# myChip register map
Vendor: ARM Ltd.; Series: ARMCM3; File version: 1.2
CPU: CM3 r2p1, little endian, no MPU, no FPU, 3 interrupt priority bits
Registers are 32-bit, read-write, reset 0x0 unless marked. A register's access mark holds for its fields unless they carry their own. Offsets are from the block's base; [hi:lo] are bit positions; {n}, {i} and the like mark numbered series.

## RCU
Base 0x40020000
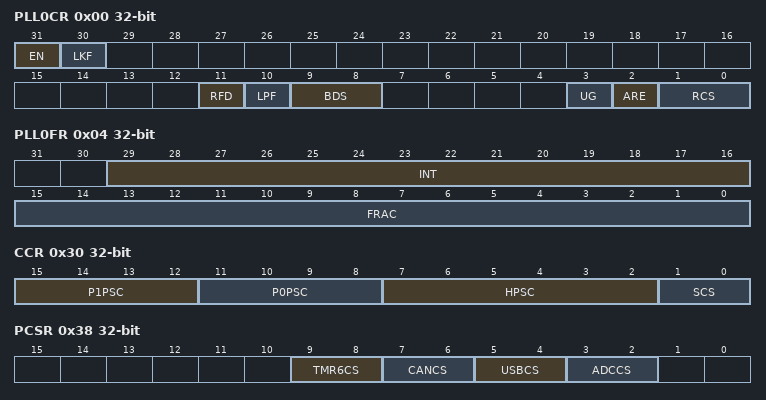
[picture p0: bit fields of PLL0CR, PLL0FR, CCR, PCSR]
0x00 PLL0CR — PLL0 Control Register
  [31] EN — PLL0使能(PLL0 Enable)
  [30] LKF ro — PLL0锁定标志(PLL0 Lock Flag)
  [11] RFD — PLL0参考前除频(PLL0 Refer Clock Division)
  [10] LPF — PLL0 LPF配置(PLL0 LPF Config)
  [9:8] BDS — PLL0 VCO振荡频率范围控制(PLL0 Band Selection)
  [3] UG — PLL0倍频系数更新事件(PLL0 Update Generate)
  [2] ARE — PLL0自动加载使能(PLL0 AutoReload Enable)
  [1:0] RCS — PLL0参考时钟源(PLL0 Refer Clock Selection)
0x04 PLL0FR — PLL0 Fractional Register
  [29:16] INT — PLL0倍频系数整数部分(PLL0 Integer part of multiplication factor)
  [15:0] FRAC — PLL0倍频系数小数部分(PLL0 Fractional part of multiplication factor)
0x30 CCR — System Clock Config Register
  [15:12] P1PSC — APB1时钟分频配置(APB1 Clock Prescale)
  [11:8] P0PSC — APB0时钟分频配置(APB0 Clock Prescale)
  [7:2] HPSC — AHB时钟分频配置(AHB Clock Prescale)
  [1:0] SCS — 系统时钟源选择(System Clock Selection)
0x38 PCSR — Peripheral Function Clock Source Register
  [9:8] TMR6CS — TMR6时钟源选择(TMR6 Clock Source Selection)
  [7:6] CANCS — CAN时钟源选择(CAN Clock Source Selection)
  [5:4] USBCS — USB时钟源选择(USB Clock Source Selection)
  [3:2] ADCCS — ADC时钟源选择(ADC Clock Source Selection)
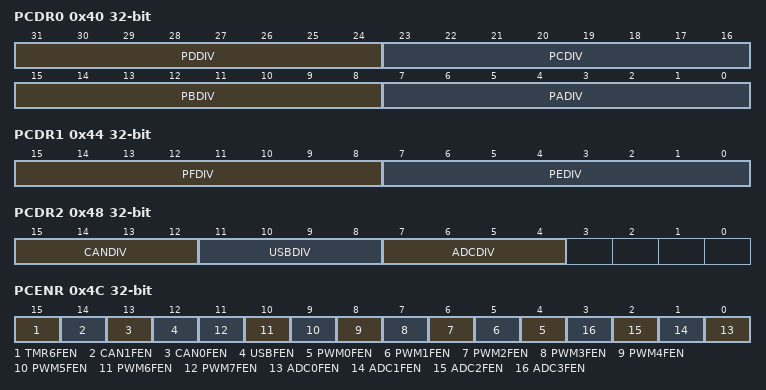
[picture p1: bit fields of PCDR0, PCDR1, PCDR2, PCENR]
0x40 PCDR0 — Peripheral Function Clock Division Register0
  [31:24] PDDIV — GPIOD消抖时钟分频(GPIOD Debounce Clock Division)
  [23:16] PCDIV — GPIOC消抖时钟分频(GPIOC Debounce Clock Division)
  [15:8] PBDIV — GPIOB消抖时钟分频(GPIOB Debounce Clock Division)
  [7:0] PADIV — GPIOA消抖时钟分频(GPIOA Debounce Clock Division)
0x44 PCDR1 — Peripheral Function Clock Division Register1
  [15:8] PFDIV — GPIOF消抖时钟分频(GPIOF Debounce Clock Division)
  [7:0] PEDIV — GPIOE消抖时钟分频(GPIOE Debounce Clock Division)
0x48 PCDR2 — Peripheral Function Clock Division Register2
  [15:12] CANDIV — CAN时钟分频选择(CAN Clock Division)
  [11:8] USBDIV — USB时钟分频选择(USB Clock Division)
  [7:4] ADCDIV — ADC时钟分频选择(ADC Clock Division)
0x4C PCENR — Peripheral Function Clock Enable Register
  [15] TMR6FEN — TMR6功能时钟使能(TMR6 Function Clock Enable)
  [14] CAN1FEN — CAN1功能时钟使能(CAN1 Function Clock Enable)
  [13] CAN0FEN — CAN0功能时钟使能(CAN0 Function Clock Enable)
  [12] USBFEN — USB功能时钟使能(USB Function Clock Enable)
  [n+4] PWM{n}FEN (n=0..7) — PWM{n}功能时钟使能(PWM{n} Function Clock Enable)
  [n] ADC{n}FEN (n=0..3) — ADC{n}功能时钟使能(ADC{n} Function Clock Enable)
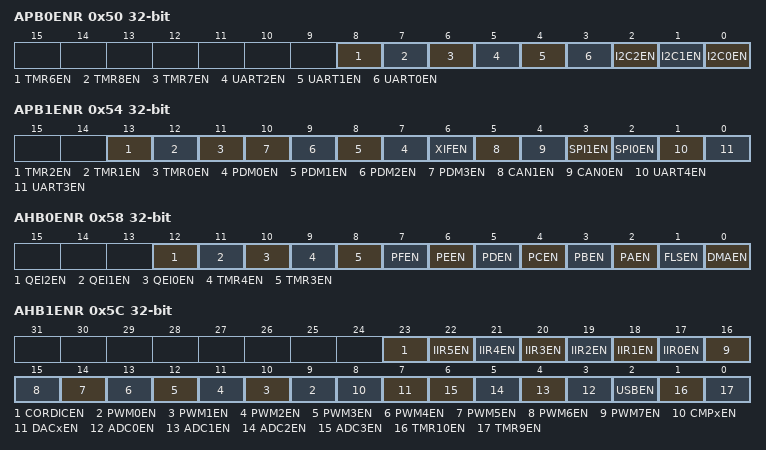
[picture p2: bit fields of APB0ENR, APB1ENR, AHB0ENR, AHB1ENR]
0x50 APB0ENR — APB0 Peripheral Clock Enable Register
  [8] TMR6EN — TMR6时钟使能(TMR6 Clock Enable)
  [7] TMR8EN — TMR8时钟使能(TMR8 Clock Enable)
  [6] TMR7EN — TMR7时钟使能(TMR7 Clock Enable)
  [5] UART2EN — UART2时钟使能(UART2 Clock Enable)
  [4] UART1EN — UART1时钟使能(UART1 Clock Enable)
  [3] UART0EN — UART0时钟使能(UART0 Clock Enable)
  [2] I2C2EN — I2C2时钟使能(I2C2 Clock Enable)
  [1] I2C1EN — I2C1时钟使能(I2C1 Clock Enable)
  [0] I2C0EN — I2C0时钟使能(I2C0 Clock Enable)
0x54 APB1ENR — APB1 Peripheral Clock Enable Register
  [13] TMR2EN — TMR2时钟使能(TMR2 Clock Enable)
  [12] TMR1EN — TMR1时钟使能(TMR1 Clock Enable)
  [11] TMR0EN — TMR0时钟使能(TMR0 Clock Enable)
  [n+7] PDM{n}EN (n=0..3) — PDM{n}时钟使能(PDM{n} Clock Enable)
  [6] XIFEN — XIF时钟使能(XIF Clock Enable)
  [5] CAN1EN — CAN1时钟使能(CAN1 Clock Enable)
  [4] CAN0EN — CAN0时钟使能(CAN0 Clock Enable)
  [3] SPI1EN — SPI1时钟使能(SPI1 Clock Enable)
  [2] SPI0EN — SPI0时钟使能(SPI0 Clock Enable)
  [1] UART4EN — UART4时钟使能(UART4 Clock Enable)
  [0] UART3EN — UART3时钟使能(UART3 Clock Enable)
0x58 AHB0ENR — AHB0 Peripheral Clock Enable Register
  [12] QEI2EN — QEI2时钟使能(QEI2 Clock Enable)
  [11] QEI1EN — QEI1时钟使能(QEI1 Clock Enable)
  [10] QEI0EN — QEI0时钟使能(QEI0 Clock Enable)
  [9] TMR4EN — TMR4时钟使能(TMR4 Clock Enable)
  [8] TMR3EN — TMR3时钟使能(TMR3 Clock Enable)
  [7] PFEN — GPIOF时钟使能(GPIOF Clock Enable)
  [6] PEEN — GPIOE时钟使能(GPIOE Clock Enable)
  [5] PDEN — GPIOD时钟使能(GPIOD Clock Enable)
  [4] PCEN — GPIOC时钟使能(GPIOC Clock Enable)
  [3] PBEN — GPIOB时钟使能(GPIOB Clock Enable)
  [2] PAEN — GPIOA时钟使能(GPIOA Clock Enable)
  [1] FLSEN — FLASH时钟使能(FLASH Clock Enable)
  [0] DMAEN — DMA时钟使能(DMA Clock Enable)
0x5C AHB1ENR — AHB1 Peripheral Clock Enable Register
  [23] CORDICEN — CORDIC时钟使能(CORDIC Clock Enable)
  [n+17] IIR{n}EN (n=0..5) — IIR{n}时钟使能(IIR{n} Clock Enable)
  [n+9] PWM{n}EN (n=0..7) — PWM{n}时钟使能(PWM{n} Clock Enable)
  [8] CMPxEN — CMPx时钟使能(CMPx Clock Enable)
  [7] DACxEN — DACx时钟使能(DACx Clock Enable)
  [n+3] ADC{n}EN (n=0..3) — ADC{n}时钟使能(ADC{n} Clock Enable)
  [2] USBEN — USB时钟使能(USB Clock Enable)
  [1] TMR10EN — TMR10时钟使能(TMR10 Clock Enable)
  [0] TMR9EN — TMR9时钟使能(TMR9 Clock Enable)
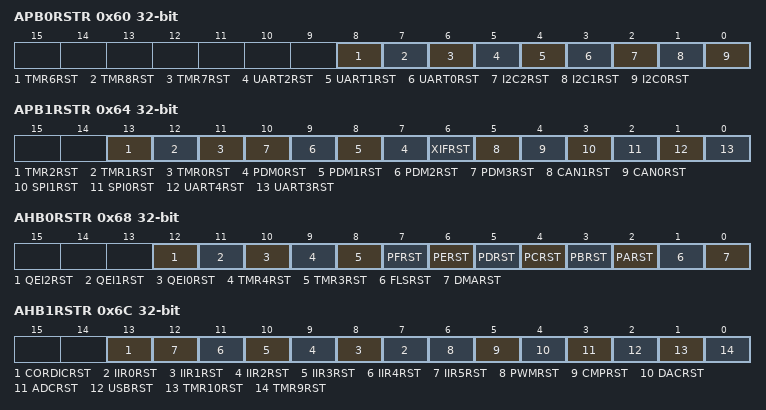
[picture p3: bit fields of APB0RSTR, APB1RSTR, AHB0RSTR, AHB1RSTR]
0x60 APB0RSTR — APB0 Peripheral Reset Register
  [8] TMR6RST — TMR6复位控制(TMR6 Reset)
  [7] TMR8RST — TMR8复位控制(TMR8 Reset)
  [6] TMR7RST — TMR7复位控制(TMR7 Reset)
  [5] UART2RST — UART2复位控制(UART2 Reset)
  [4] UART1RST — UART1复位控制(UART1 Reset)
  [3] UART0RST — UART0复位控制(UART0 Reset)
  [2] I2C2RST — I2C2复位控制(I2C2 Reset)
  [1] I2C1RST — I2C1复位控制(I2C1 Reset)
  [0] I2C0RST — I2C0复位控制(I2C0 Reset)
0x64 APB1RSTR — APB1 Peripheral Reset Register
  [13] TMR2RST — TMR2复位控制(TMR1 Reset)
  [12] TMR1RST — TMR1复位控制(TMR1 Reset)
  [11] TMR0RST — TMR0复位控制(TMR0 Reset)
  [n+7] PDM{n}RST (n=0..3) — PDM{n}复位控制(PDM{n} Reset)
  [6] XIFRST — XIF复位控制(XIF Reset)
  [5] CAN1RST — CAN1复位控制(CAN1 Reset)
  [4] CAN0RST — CAN0复位控制(CAN0 Reset)
  [3] SPI1RST — SPI1复位控制(SPI1 Reset)
  [2] SPI0RST — SPI0复位控制(SPI0 Reset)
  [1] UART4RST — UART4复位控制(UART4 Reset)
  [0] UART3RST — UART3复位控制(UART3 Reset)
0x68 AHB0RSTR — AHB0 Peripheral Reset Register
  [12] QEI2RST — QEI2复位控制(QEI2 Reset)
  [11] QEI1RST — QEI1复位控制(QEI1 Reset)
  [10] QEI0RST — QEI0复位控制(QEI0 Reset)
  [9] TMR4RST — TMR4复位控制(TMR4 Reset)
  [8] TMR3RST — TMR3复位控制(TMR3 Reset)
  [7] PFRST — GPIOF复位控制(GPIOF Reset)
  [6] PERST — GPIOE复位控制(GPIOE Reset)
  [5] PDRST — GPIOD复位控制(GPIOD Reset)
  [4] PCRST — GPIOC复位控制(GPIOC Reset)
  [3] PBRST — GPIOB复位控制(GPIOB Reset)
  [2] PARST — GPIOA复位控制(GPIOA Reset)
  [1] FLSRST — FLASH复位控制(FLASH Reset)
  [0] DMARST — DMA复位控制(DMA Reset)
0x6C AHB1RSTR — AHB1 Peripheral Reset Register
  [13] CORDICRST — CORDIC复位控制(CORDIC Reset)
  [n+7] IIR{n}RST (n=0..5) — IIR{n}复位控制(IIR{n} Reset)
  [6] PWMRST — PWM复位控制(PWM Reset)
  [5] CMPRST — CMP复位控制(CMP Reset)
  [4] DACRST — DAC复位控制(DAC Reset)
  [3] ADCRST — ADC复位控制(ADC Reset)
  [2] USBRST — USB复位控制(USB Reset)
  [1] TMR10RST — TMR10复位控制(TMR10 Reset)
  [0] TMR9RST — TMR9复位控制(TMR9 Reset)
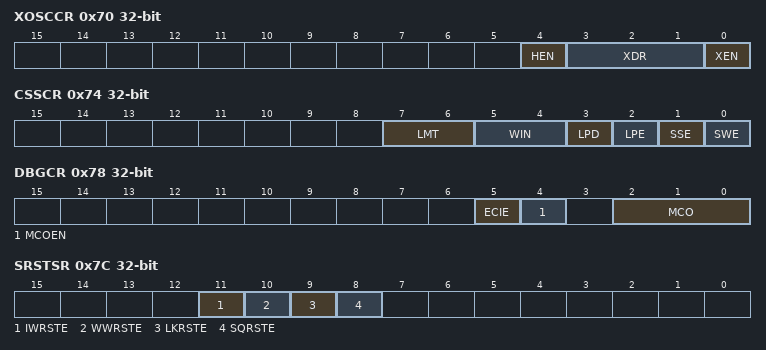
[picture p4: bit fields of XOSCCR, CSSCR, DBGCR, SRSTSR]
0x70 XOSCCR — XOSC Control Register
  [4] HEN — HSI使能(HSI Enable)
  [3:1] XDR — HSE启动电流配置(HSE Charge Pump Selection)
  [0] XEN — HSE使能(HSE Enable)
0x74 CSSCR — Clock Secure Control Register
  [7:6] LMT — XOSC比较阈值宽度(XOSC Limit Window Width)
  [5:4] WIN — XOSC计数窗口宽度调整(XOSC AutoSwitch Window Width)
  [3] LPD ro — 外部晶振异常NMI中断状态(XOSC Loss Pending)
  [2] LPE — 外部晶振异常NMI中断使能(XOSC Loss NMI Enable)
  [1] SSE — 系统时钟切换使能(SYSCLK Switch Enable)
  [0] SWE — 外部晶振安全监测使能(XOSC Securce Switch Enable)
0x78 DBGCR — Internal Clock Fanout Register
  [5] ECIE — 芯片外部时钟输入使能(External Clock Input Enable)
  [4] MCOEN — 芯片内部时钟输出使能(Internal Clock Fanout Enable)
  [2:0] MCO — 芯片内部时钟输出源选择(Internal Clock Fanout Source)
0x7C SRSTSR — System RstStatus Register
  [11] IWRSTE — IWDG Reset Enable
  [10] WWRSTE — WWDG Reset Enable
  [9] LKRSTE — LKUP Reset Enable
  [8] SQRSTE — SystemREQ Reset Enable
0x80 KEYR — LockKey Register
  [0] KEY — 寄存器写保护(Register LockKey)
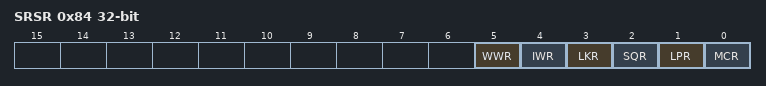
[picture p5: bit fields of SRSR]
0x84 SRSR — System Reset Status Register
  [5] WWR — WWDG复位标志位(WWDG Reset Status)
  [4] IWR — IWDG复位标志位(IWDG Reset Status)
  [3] LKR — LOCKUP复位标志位(LOCKUP Reset Status)
  [2] SQR — SystemREQ复位标志位(SystemREQ Reset Status)
  [1] LPR — LVD复位标志位(LVD Reset Status)
  [0] MCR — MCLR复位标志位(MCLR Reset Status)
